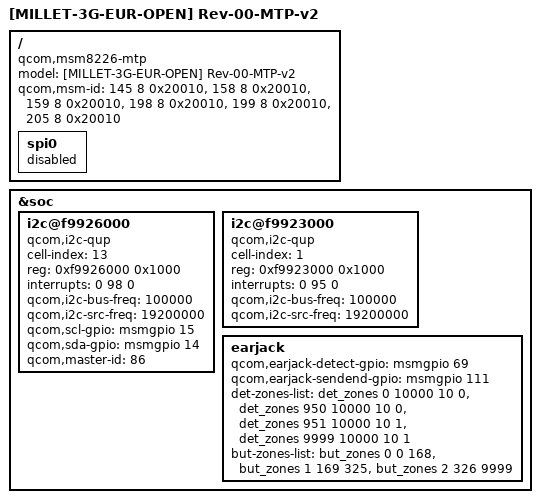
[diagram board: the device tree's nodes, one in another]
/* Copyright (c) 2013, The Linux Foundation. All rights reserved.
 *
 * This program is free software; you can redistribute it and/or modify
 * it under the terms of the GNU General Public License version 2 and
 * only version 2 as published by the Free Software Foundation.
 *
 * This program is distributed in the hope that it will be useful,
 * but WITHOUT ANY WARRANTY; without even the implied warranty of
 * MERCHANTABILITY or FITNESS FOR A PARTICULAR PURPOSE.  See the
 * GNU General Public License for more details.
 */

/* qcom,msm-id =<Chip_id Board_version Other_Specific_info>
 * All these three fields are unsigned 32 bit integers
 * For OtherSpecificInfo = 0xABCDEFGH [32 bits in total]
 *  G[4BITS]:MODEL_VARIANT i.e. 0 for MS01,1 for MILLET_3G, 2 for CT01, 3 for S3VE
 *  H[4BITS]:Hardware Revision
 * Please refer to .../lk/platform/msm_shared/dev_tree.c also
 */ 
 
/dts-v1/;
/include/ "msm8226-v2.dtsi"
/include/ "msm8226-sec-millet3geur-r00.dtsi"

/ {
	model = "[MILLET-3G-EUR-OPEN] Rev-00-MTP-v2";
	compatible = "qcom,msm8226-mtp", "qcom,msm8226", "qcom,mtp";
	qcom,msm-id = <145 8 0x20010>,
		      <158 8 0x20010>,
		      <159 8 0x20010>,
		      <198 8 0x20010>,
		      <199 8 0x20010>,
		      <205 8 0x20010>;
};

/{
        spi0{
        status = "disable";
        };

};

&soc {
	/*Adding node for the MAX77693 I2C QUP Interface*/
        i2c@f9926000 { /* BLSP-1 QUP-3 */
                cell-index = <13>;
                compatible = "qcom,i2c-qup";
                reg = <0xf9926000 0x1000>;
                #address-cells = <1>;
                #size-cells = <0>;
                reg-names = "qup_phys_addr";
                interrupts = <0 98 0>;
                interrupt-names = "qup_err_intr";
                qcom,i2c-bus-freq = <100000>;
                qcom,i2c-src-freq = <19200000>;
                qcom,scl-gpio = <&msmgpio 15 0>;
                qcom,sda-gpio = <&msmgpio 14 0>;
                qcom,master-id = <86>;
	};

	i2c@f9923000 { /* BLSP-1 QUP-1 */
		cell-index = <1>;
		compatible = "qcom,i2c-qup";
		reg = <0xf9923000 0x1000>;
		#address-cells = <1>;
		#size-cells = <0>;
		reg-names = "qup_phys_addr";
		interrupts = <0 95 0>;
		interrupt-names = "qup_err_intr";
		qcom,i2c-bus-freq = <100000>;
		qcom,i2c-src-freq = <19200000>;
		status = "okay";
	};

	earjack {
                /*Override GPIO properties*/
                qcom,earjack-detect-gpio = <&msmgpio 69 0>;
                qcom,earjack-sendend-gpio = <&msmgpio 111 0>;
				det-zones-list = <&det_zones 0 10000 10 0>,
                             <&det_zones 950 10000 10 0>,
                             <&det_zones 951 10000 10 1>,
                             <&det_zones 9999 10000 10 1>;
				but-zones-list = <&but_zones 0 0 168>,
                             <&but_zones 1 169 325>,
                             <&but_zones 2 326 9999>;
        };
};


